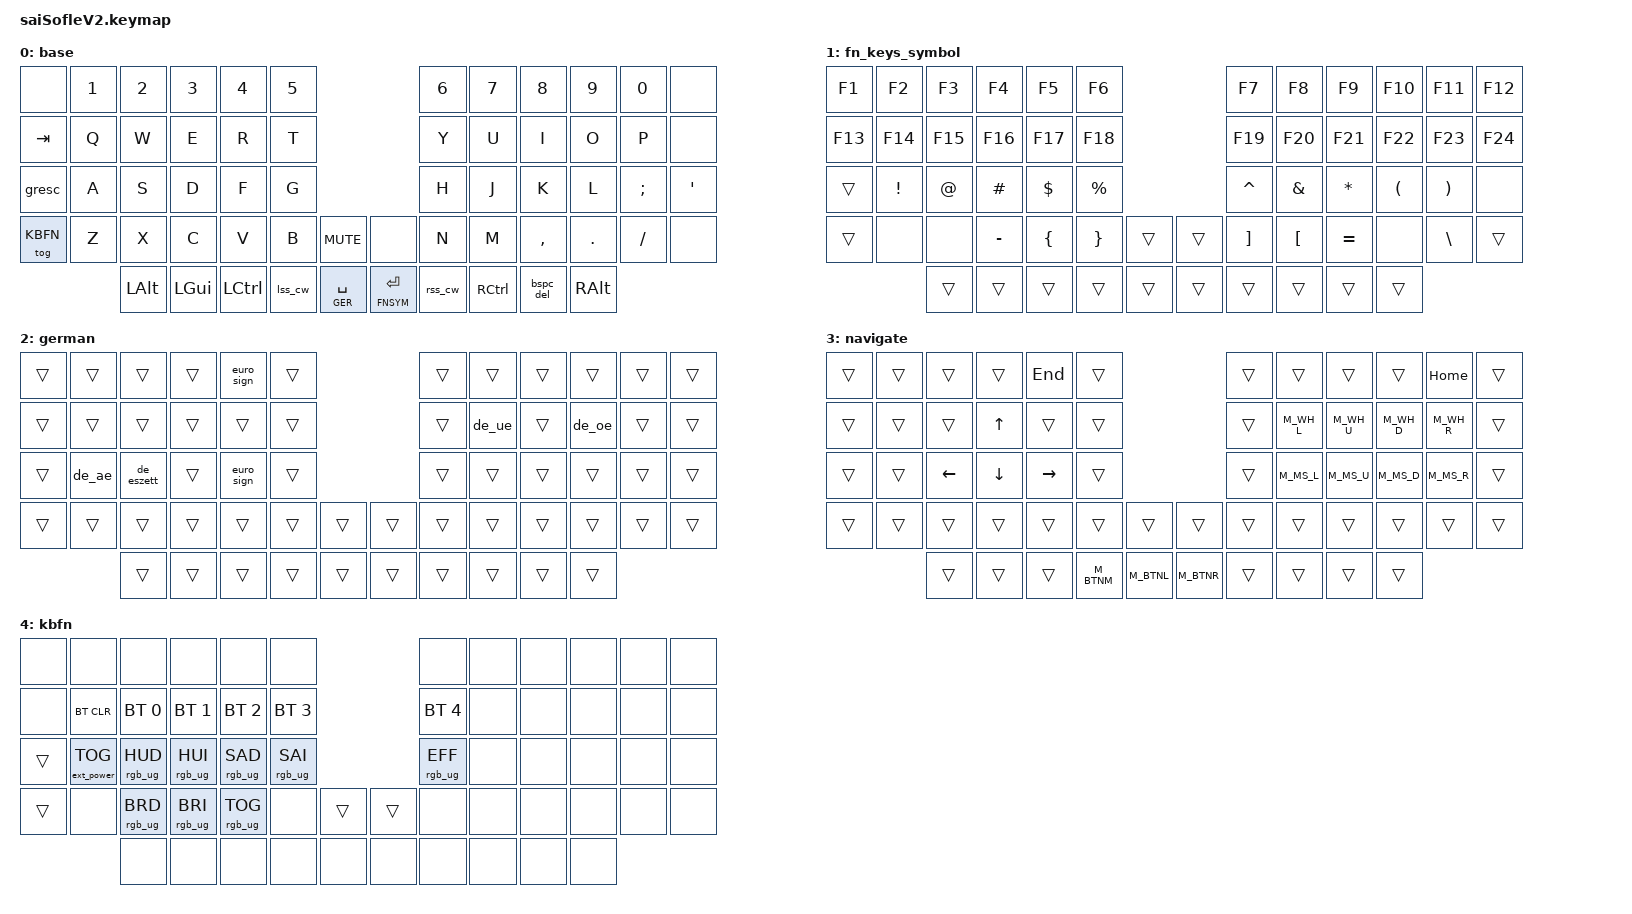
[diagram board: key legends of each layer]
#include <behaviors.dtsi>
#include <dt-bindings/zmk/keys.h>
#include <dt-bindings/zmk/bt.h>
#include <dt-bindings/zmk/rgb.h>
#include <dt-bindings/zmk/ext_power.h>

#include "../../../../zmk-nodefree-config/helper.h"
#include "../../../../zmk-nodefree-config/mouse.dtsi"
#include "../../../../zmk-nodefree-config/keypos_def/keypos_60keys.h"
#include "../../../../zmk-nodefree-config/international_chars/german.dtsi"

#define ______ &trans

#define BASE 0
#define FNSYM 1
#define GER 2
#define NAV 3
#define KBFN 4

// euro sign
ZMK_UNICODE_SINGLE(euro_sign, N2, N0, A, C)  // €

/ {

    /**
    * Custom Behaviors
    */
    // tap-dance
    // tap: sticky left shift | double tap: capsword
    behaviors {
        lss_cw: left_sticky_shift_capsword{
            compatible = "zmk,behavior-tap-dance";
            label = "left_sticky_shift_capsword";
            #binding-cells = <0>;
            tapping-term-ms =<200>;
            bindings =<&sk LSHFT>, <&caps_word>;
        };
    };

    // tap: sticky right shift | double tap: capsword
    behaviors {
        rss_cw: right_sticky_shift_capsword{
            compatible = "zmk,behavior-tap-dance";
            label = "right_sticky_shift_capsword";
            #binding-cells = <0>;
            tapping-term-ms =<200>;
            bindings =<&sk RSHFT>, <&caps_word>;
        };
    };

    // hold: FNSYM layer | tap: RET | double tap: NAV
    behaviors {
        fnsm_ret_nav: lt_fnsym_ret_tog_nav{
            compatible = "zmk,behavior-tap-dance";
            label = "fnsym_ret_nav";
            #binding-cells = <0>;
            tapping-term-ms =<200>;
            bindings =<&lt FNSYM RET>, <&tog NAV>;
        };
    };

    // hold: GER layer | tap: SPACE | double tap: KBFN
    behaviors {
        ger_spc_kbfn: lt_ger_space_tog_kbfn{
            compatible = "zmk,behavior-tap-dance";
            label = "ger_space_kbfn";
            #binding-cells = <0>;
            tapping-term-ms =<200>;
            bindings =<&lt GER SPACE>, <&tog KBFN>;
        };
    };

    // mod-morph
    // tap: backspace | shift + tap: delete
    behaviors {
        bspc_del: backspace_delete{
            compatible = "zmk,behavior-mod-morph";
            label = "backspace_delete";
            #binding-cells = <0>;
            bindings = <&kp BSPC>, <&kp DEL>;
            mods = <(MOD_LSFT|MOD_RSFT)>;
        };
    };


    // macro
    // windows shut-down
    behaviors {
        win_shtdwn: windows_shutdown{
            compatible = "zmk,behavior-macro";
            label = "windows_shutdown";
            #binding-cells = <0>;
            wait-ms = <100>;
            tap-ms = <5>;
            bindings = <&kp LG(X) &kp U &kp U>;
        };
    };

    // windows restart
    behaviors {
        win_restrt: windows_restart{
            compatible = "zmk,behavior-macro";
            label = "windows_restart";
            #binding-cells = <0>;
            wait-ms = <100>;
            tap-ms = <5>;
            bindings = <&kp LG(X) &kp U &kp R>;
        };
    };

    // layers
   // Activate keyboard function layer by pressing raise and lower
    conditional_layers {
        compatible = "zmk,conditional-layers";
        nav_layer {
            if-layers = <FNSYM GER>;
            then-layer = <NAV>;
        };
    };

    keymap {
        compatible = "zmk,keymap";

        base_layer {
            label = "base";
            bindings = <
                // ╭─────────────┬─────────────┬─────────────┬─────────────┬─────────────┬─────────────╮                                ╭───────────────┬─────────────┬─────────────┬─────────────┬─────────────┬─────────────╮
                     &none         &kp N1        &kp N2        &kp N3        &kp N4        &kp N5                                         &kp N6          &kp N7        &kp N8        &kp N9        &kp N0        &none
                // ├─────────────┼─────────────┼─────────────┼─────────────┼─────────────┼─────────────┤                                ├───────────────┼─────────────┼─────────────┼─────────────┼─────────────┼─────────────┤
                     &kp TAB       &kp Q         &kp W         &kp E         &kp R         &kp T                                          &kp Y           &kp U         &kp I         &kp O         &kp P         &none
                // ├─────────────┼─────────────┼─────────────┼─────────────┼─────────────┼─────────────┤                                ├───────────────┼─────────────┼─────────────┼─────────────┼─────────────┼─────────────┤
                     &gresc        &kp A         &kp S         &kp D         &kp F         &kp G                                          &kp H           &kp J         &kp K         &kp L         &kp SEMI      &kp SQT
                // ├─────────────┼─────────────┼─────────────┼─────────────┼─────────────┼─────────────┼─────────────╮    ╭─────────────┼───────────────┼─────────────┼─────────────┼─────────────┼─────────────┼─────────────┤
                     &tog KBFN     &kp Z         &kp X         &kp C         &kp V         &kp B         &kp C_MUTE         &none         &kp N           &kp M         &kp COMMA     &kp DOT       &kp FSLH      &none
                // ╰─────────────┴─────────────┼─────────────┼─────────────┼─────────────┼─────────────┼─────────────┤    ├─────────────┼───────────────┼─────────────┼─────────────┼─────────────┼─────────────┴─────────────╯
                                                 &kp LALT      &kp LGUI      &kp LCTRL     &lss_cw      &lt GER SPACE      &lt FNSYM RET  &rss_cw         &kp RCTRL     &bspc_del     &kp RALT
                //                             ╰─────────────┴─────────────┴─────────────┴─────────────┴─────────────╯    ╰─────────────┴───────────────┴─────────────┴─────────────┴─────────────╯
            >;

            sensor-bindings = <&inc_dec_kp C_VOL_UP C_VOL_DN &inc_dec_kp PG_UP PG_DN>;
        };

        fnsym_layer {
            label = "fn_keys_symbol";
            bindings = <
                // ╭─────────────┬─────────────┬─────────────┬─────────────┬─────────────┬─────────────╮                                ╭─────────────┬─────────────┬─────────────────┬─────────────┬─────────────┬─────────────╮
                     &kp F1        &kp F2        &kp F3        &kp F4        &kp F5        &kp F6                                         &kp F7        &kp F8        &kp F9            &kp F10       &kp F11       &kp F12
                // ├─────────────┼─────────────┼─────────────┼─────────────┼─────────────┼─────────────┤                                ├─────────────┼─────────────┼─────────────────┼─────────────┼─────────────┼─────────────┤
                     &kp F13       &kp F14       &kp F15       &kp F16       &kp F17       &kp F18                                        &kp F19       &kp F20       &kp F21           &kp F22       &kp F23       &kp F24
                // ├─────────────┼─────────────┼─────────────┼─────────────┼─────────────┼─────────────┤                                ├─────────────┼─────────────┼─────────────────┼─────────────┼─────────────┼─────────────┤
                     ______        &kp EXCL      &kp AT        &kp HASH      &kp DLLR      &kp PRCNT                                      &kp CARET     &kp AMPS      &kp STAR          &kp LPAR      &kp RPAR      &none
                // ├─────────────┼─────────────┼─────────────┼─────────────┼─────────────┼─────────────┼─────────────╮    ╭─────────────┼─────────────┼─────────────┼─────────────────┼─────────────┼─────────────┼─────────────┤
                     ______        &none         &none         &kp MINUS     &kp LBRC      &kp RBRC      ______             ______        &kp RBKT      &kp LBKT      &kp EQUAL         &none         &kp BSLH      ______
                // ╰─────────────┴─────────────┼─────────────┼─────────────┼─────────────┼─────────────┼─────────────┤    ├─────────────┼─────────────┼─────────────┼─────────────────┼─────────────┼─────────────┴─────────────╯
                                                 ______        ______        ______        ______        ______             ______        ______        ______         ______           ______
                //                             ╰─────────────┴─────────────┴─────────────┴─────────────┴─────────────╯    ╰─────────────┴─────────────┴─────────────┴─────────────────┴─────────────╯
            >;

            sensor-bindings = <&inc_dec_kp C_VOL_UP C_VOL_DN &inc_dec_kp PG_UP PG_DN>;
        };

        ger_layer {
            label = "german";
            bindings = <
                // ╭─────────────┬─────────────┬─────────────┬─────────────┬─────────────┬─────────────╮                                ╭─────────────┬─────────────┬─────────────────┬─────────────┬─────────────┬─────────────╮
                     ______        ______        ______        ______        &euro_sign    ______                                         ______        ______        ______            ______        ______        ______
                // ├─────────────┼─────────────┼─────────────┼─────────────┼─────────────┼─────────────┤                                ├─────────────┼─────────────┼─────────────────┼─────────────┼─────────────┼─────────────┤
                     ______        ______        ______        ______        ______        ______                                         ______        &de_ue        ______            &de_oe        ______        ______
                // ├─────────────┼─────────────┼─────────────┼─────────────┼─────────────┼─────────────┤                                ├─────────────┼─────────────┼─────────────────┼─────────────┼─────────────┼─────────────┤
                     ______        &de_ae        &de_eszett    ______        &euro_sign    ______                                         ______        ______        ______            ______        ______        ______
                // ├─────────────┼─────────────┼─────────────┼─────────────┼─────────────┼─────────────┼─────────────╮    ╭─────────────┼─────────────┼─────────────┼─────────────────┼─────────────┼─────────────┼─────────────┤
                     ______        ______        ______        ______        ______        ______        ______             ______        ______        ______        ______            ______        ______        ______
                // ╰─────────────┴─────────────┼─────────────┼─────────────┼─────────────┼─────────────┼─────────────┤    ├─────────────┼─────────────┼─────────────┼─────────────────┼─────────────┼─────────────┴─────────────╯
                                                 ______        ______        ______        ______        ______             ______        ______        ______         ______           ______
                //                             ╰─────────────┴─────────────┴─────────────┴─────────────┴─────────────╯    ╰─────────────┴─────────────┴─────────────┴─────────────────┴─────────────╯
            >;

            sensor-bindings = <&inc_dec_kp C_VOL_UP C_VOL_DN &inc_dec_kp PG_UP PG_DN>;
        };

        nav_layer {
        label = "navigate";
            bindings = <
                // ╭─────────────┬─────────────┬─────────────┬─────────────┬─────────────┬─────────────╮                                ╭─────────────┬─────────────┬─────────────────┬─────────────┬─────────────┬─────────────╮
                     ______        ______        ______        ______        &kp END       ______                                         ______        ______        ______            ______        &kp HOME      ______
                // ├─────────────┼─────────────┼─────────────┼─────────────┼─────────────┼─────────────┤                                ├─────────────┼─────────────┼─────────────────┼─────────────┼─────────────┼─────────────┤
                     ______        ______        ______        &kp UP        ______        ______                                         ______        M_WH_L        M_WH_U            M_WH_D        M_WH_R         ______
                // ├─────────────┼─────────────┼─────────────┼─────────────┼─────────────┼─────────────┤                                ├─────────────┼─────────────┼─────────────────┼─────────────┼─────────────┼─────────────┤
                     ______        ______        &kp LEFT      &kp DOWN      &kp RIGHT     ______                                         ______        M_MS_L        M_MS_U            M_MS_D        M_MS_R        ______
                // ├─────────────┼─────────────┼─────────────┼─────────────┼─────────────┼─────────────┼─────────────╮    ╭─────────────┼─────────────┼─────────────┼─────────────────┼─────────────┼─────────────┼─────────────┤
                     ______        ______        ______        ______        ______        ______        ______             ______        ______        ______        ______            ______        ______        ______
                // ╰─────────────┴─────────────┼─────────────┼─────────────┼─────────────┼─────────────┼─────────────┤    ├─────────────┼─────────────┼─────────────┼─────────────────┼─────────────┼─────────────┴─────────────╯
                                                 ______        ______        ______        M_BTNM        M_BTNL             M_BTNR       ______        ______         ______            ______
                //                             ╰─────────────┴─────────────┴─────────────┴─────────────┴─────────────╯    ╰─────────────┴─────────────┴─────────────┴─────────────────┴─────────────╯
            >;

            sensor-bindings = <&inc_dec_kp C_VOL_UP C_VOL_DN &inc_dec_kp PG_UP PG_DN>;
        };

        kbfn_layer {
        label = "kbfn";
            bindings = <
                // ╭─────────────┬─────────────────┬────────────────┬────────────────┬────────────────┬────────────────╮                                ╭────────────────┬─────────────┬─────────────────┬─────────────┬─────────────┬─────────────╮
                     &none         &none             &none            &none            &none            &none                                             &none            &none         &none             &none         &none         &none
                // ├─────────────┼─────────────────┼────────────────┼────────────────┼────────────────┼────────────────┤                                ├────────────────┼─────────────┼─────────────────┼─────────────┼─────────────┼─────────────┤
                     &none         &bt BT_CLR        &bt BT_SEL 0     &bt BT_SEL 1     &bt BT_SEL 2     &bt BT_SEL 3                                      &bt BT_SEL 4     &none         &none             &none         &none          &none
                // ├─────────────┼─────────────────┼────────────────┼────────────────┼────────────────┼────────────────┤                                ├────────────────┼─────────────┼─────────────────┼─────────────┼─────────────┼─────────────┤
                     ______       &ext_power EP_TOG  &rgb_ug RGB_HUD  &rgb_ug RGB_HUI  &rgb_ug RGB_SAD  &rgb_ug RGB_SAI                                   &rgb_ug RGB_EFF  &none         &none             &none         &none         &none
                // ├─────────────┼─────────────────┼────────────────┼────────────────┼────────────────┼────────────────┼─────────────╮    ╭─────────────┼────────────────┼─────────────┼─────────────────┼─────────────┼─────────────┼─────────────┤
                     ______        &none             &rgb_ug RGB_BRD  &rgb_ug RGB_BRI  &rgb_ug RGB_TOG  &none            ______             ______        &none            &none         &none             &none         &none         &none
                // ╰─────────────┴─────────────────┼────────────────┼────────────────┼────────────────┼────────────────┼─────────────┤    ├─────────────┼────────────────┼─────────────┼─────────────────┼─────────────┼─────────────┴─────────────╯
                                                     &none            &none            &none            &none            &none              &none         &none            &none         &none             &none
                //                                 ╰────────────────┴────────────────┴────────────────┴────────────────┴─────────────╯    ╰─────────────┴────────────────┴─────────────┴─────────────────┴─────────────╯
            >;

            sensor-bindings = <&inc_dec_kp C_VOL_UP C_VOL_DN &inc_dec_kp PG_UP PG_DN>;
        };

    };
};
